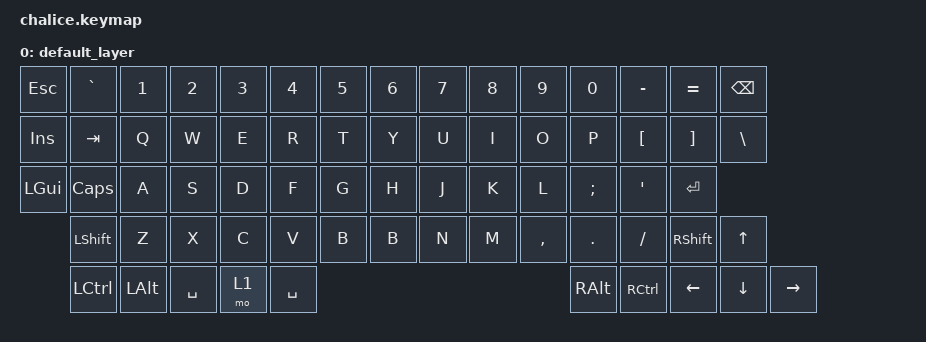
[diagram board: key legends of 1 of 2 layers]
/*
 * Copyright (c) 2020 The ZMK Contributors
 *
 * SPDX-License-Identifier: MIT
 */

#include <behaviors.dtsi>
#include <dt-bindings/zmk/keys.h>
#include <dt-bindings/zmk/bt.h>
#include <dt-bindings/zmk/rgb.h>

/ {
        keymap {
                compatible = "zmk,keymap";

                default_layer {

                        bindings = <
   &kp ESC         &kp GRAVE   &kp N1       &kp N2       &kp N3       &kp N4       &kp N5       &kp N6       &kp N7       &kp N8       &kp N9       &kp N0       &kp MINUS    &kp EQUAL    &kp BSPC
   &kp INSERT      &kp TAB     &kp Q        &kp W        &kp E        &kp R        &kp T        &kp Y        &kp U        &kp I        &kp O        &kp P        &kp LBKT     &kp RBKT     &kp BSLH
   &kp LEFT_GUI    &kp CAPS    &kp A        &kp S        &kp D        &kp F        &kp G        &kp H        &kp J        &kp K        &kp L        &kp SEMI     &kp SQT      &kp ENTER                    
                   &kp LSHFT   &kp Z        &kp X        &kp C        &kp V        &kp B        &kp B        &kp N        &kp M        &kp COMMA    &kp DOT      &kp SLASH    &kp RSHFT    &kp UP
                   &kp LCTRL                &kp LALT                  &kp SPACE    &mo 1                     &kp SPACE                 &kp RALT                  &kp RCTRL    &kp LEFT     &kp DOWN     &kp RIGHT 
                                >;
                        };

                function_layer {

                        bindings = <
   &bootloader     &trans      &kp F1       &kp F2       &kp F3       &kp F4       &kp F5       &kp F6       &kp F7       &kp F8       &kp F9       &kp F10      &kp F11      &kp F12      &trans
   &rgb_ug RGB_TOG &bt BT_CLR  &bt BT_SEL 0 &bt BT_SEL 1 &bt BT_SEL 2 &bt BT_SEL 3 &bt BT_SEL 4 &trans       &trans       &trans       &trans       &trans       &trans       &trans       &trans
   &rgb_ug RGB_SAI &trans      &trans       &trans       &trans       &trans       &trans       &trans       &trans       &trans       &trans       &trans       &trans        
                   &trans      &trans       &trans       &trans       &trans       &trans       &trans       &trans       &trans       &trans       &trans       &trans       &trans       &kp PG_UP
                   &trans                   &trans                    &trans       &trans                    &trans                    &trans                    &trans       &kp HOME     &kp PG_DN    &kp END 
                                >;
                        };
        };
};
